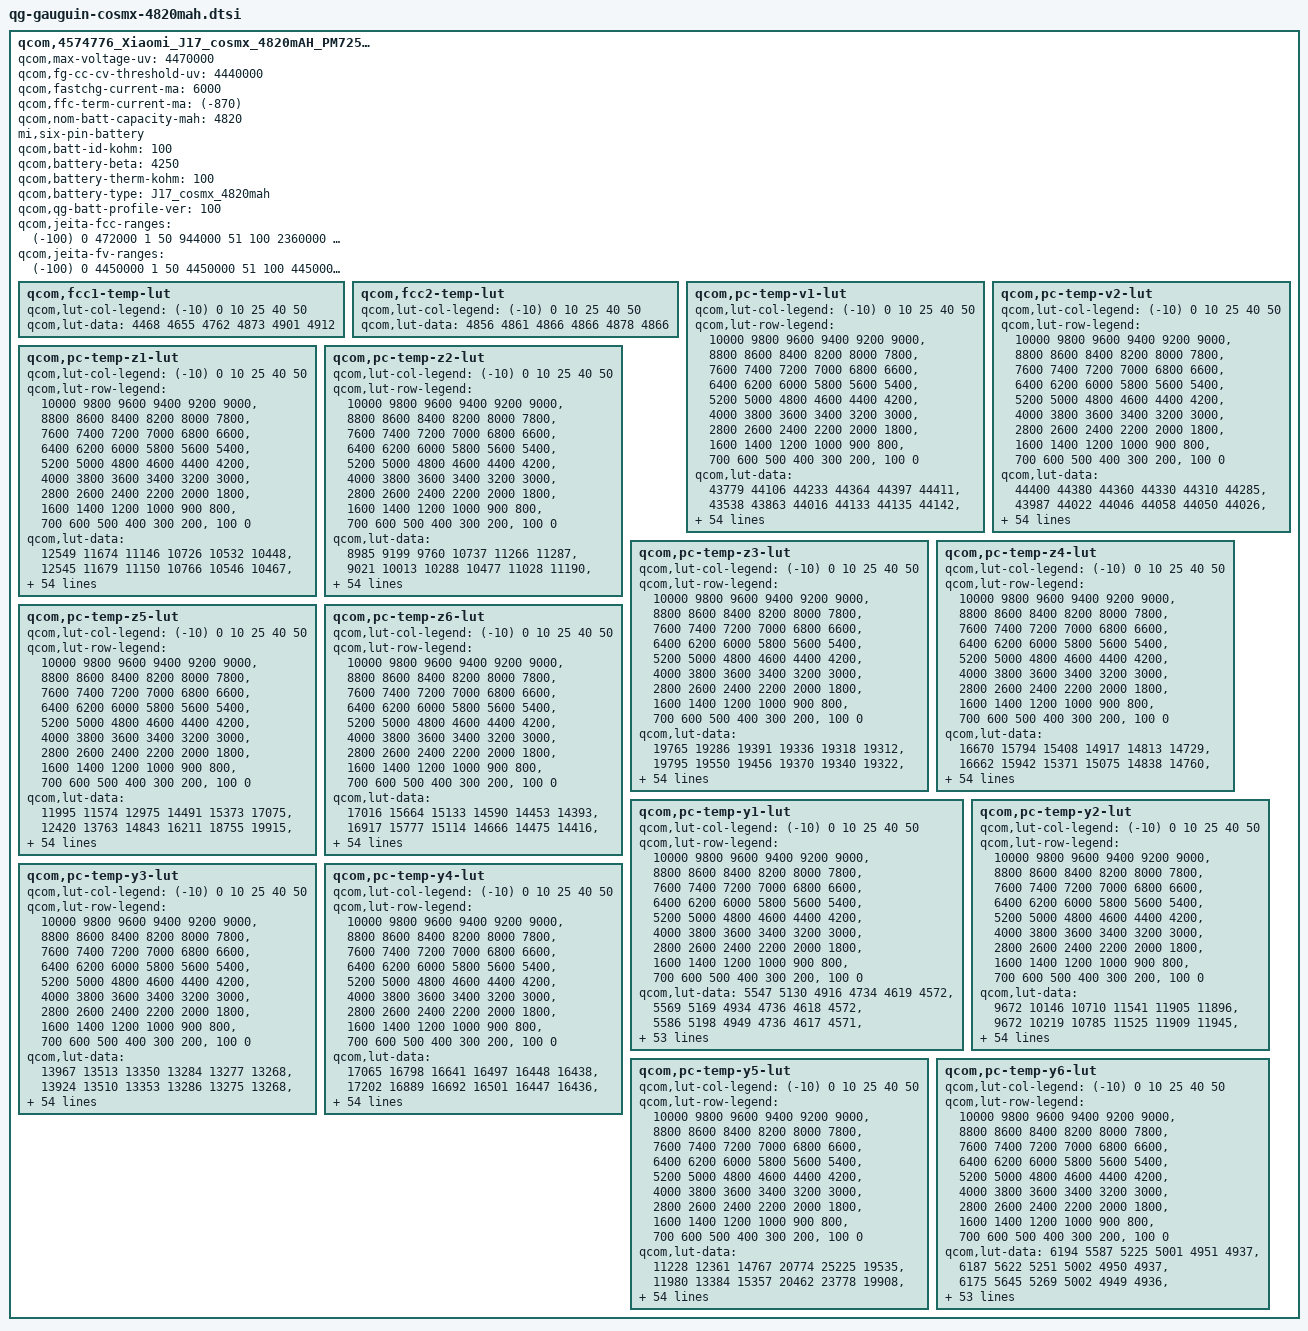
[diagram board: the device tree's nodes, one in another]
qcom,4574776_Xiaomi_J17_cosmx_4820mAH_PM7250B {
    /* 4574776_Xiaomi_J17_cosmx_4820mAH_PM7250B_averaged_MasterSlave_May19th2020 */
    qcom,max-voltage-uv = <4470000>;
    qcom,fg-cc-cv-threshold-uv = <4440000>;
    qcom,fastchg-current-ma = <6000>;
    qcom,ffc-term-current-ma = <(-870)>;
    qcom,nom-batt-capacity-mah = <4820>;
    mi,six-pin-battery;
    qcom,batt-id-kohm = <100>;
    qcom,battery-beta = <4250>;
    qcom,battery-therm-kohm = <100>;
    qcom,battery-type = "J17_cosmx_4820mah";
    qcom,qg-batt-profile-ver = <100>;
	qcom,jeita-fcc-ranges = <(-100)  0   472000
				1  50  944000
				51  100  2360000
				101 150  3776000
				151 480  6000000
				481 600  2360000>;
	qcom,jeita-fv-ranges = <(-100)  0   4450000
				1   50  4450000
				51  100  4450000
				101 150  4450000
				151 480  4480000
				481 600  4200000>;

	qcom,fcc1-temp-lut {
		qcom,lut-col-legend = <(-10) 0 10 25 40 50>;
		qcom,lut-data = <4468 4655 4762 4873 4901 4912>;
	};

	qcom,fcc2-temp-lut {
		qcom,lut-col-legend = <(-10) 0 10 25 40 50>;
		qcom,lut-data = <4856 4861 4866 4866 4878 4866>;
	};

	qcom,pc-temp-v1-lut {
		qcom,lut-col-legend = <(-10) 0 10 25 40 50>;
		qcom,lut-row-legend = <10000 9800 9600 9400 9200 9000>,
			<8800 8600 8400 8200 8000 7800>,
			<7600 7400 7200 7000 6800 6600>,
			<6400 6200 6000 5800 5600 5400>,
			<5200 5000 4800 4600 4400 4200>,
			<4000 3800 3600 3400 3200 3000>,
			<2800 2600 2400 2200 2000 1800>,
			<1600 1400 1200 1000 900 800>,
			<700 600 500 400 300 200>,
			<100 0>;
		qcom,lut-data = <43779 44106 44233 44364 44397 44411>,
			<43538 43863 44016 44133 44135 44142>,
			<43293 43634 43797 43920 43918 43921>,
			<43045 43409 43578 43709 43713 43713>,
			<42799 43176 43355 43490 43497 43498>,
			<42560 42937 43123 43266 43277 43282>,
			<42326 42697 42880 43033 43048 43057>,
			<42099 42457 42636 42791 42807 42822>,
			<41877 42218 42394 42544 42562 42580>,
			<41661 41984 42152 42298 42318 42337>,
			<41453 41756 41915 42051 42075 42091>,
			<41255 41534 41680 41811 41834 41850>,
			<41059 41315 41453 41575 41595 41614>,
			<40861 41102 41234 41344 41361 41381>,
			<40659 40894 41020 41121 41133 41153>,
			<40464 40694 40812 40905 40912 40930>,
			<40271 40499 40605 40696 40700 40714>,
			<40087 40304 40408 40493 40496 40507>,
			<39926 40110 40230 40300 40302 40309>,
			<39791 39931 40060 40126 40121 40125>,
			<39661 39782 39877 39950 39946 39949>,
			<39522 39641 39677 39727 39740 39747>,
			<39380 39484 39469 39461 39494 39509>,
			<39239 39309 39240 39239 39269 39284>,
			<39091 39130 39002 39075 39084 39096>,
			<38944 38941 38852 38934 38923 38929>,
			<38820 38753 38770 38808 38787 38789>,
			<38709 38632 38703 38695 38671 38670>,
			<38620 38561 38623 38594 38567 38561>,
			<38572 38505 38541 38503 38469 38459>,
			<38544 38454 38469 38422 38382 38366>,
			<38515 38410 38403 38349 38303 38281>,
			<38470 38368 38345 38284 38231 38203>,
			<38416 38329 38295 38226 38166 38133>,
			<38372 38292 38252 38177 38112 38075>,
			<38343 38257 38213 38130 38058 38018>,
			<38314 38226 38181 38086 38000 37949>,
			<38271 38188 38146 38043 37939 37869>,
			<38207 38125 38085 37983 37866 37784>,
			<38126 38037 37987 37893 37779 37696>,
			<38024 37933 37875 37785 37679 37597>,
			<37892 37801 37753 37664 37562 37480>,
			<37736 37657 37611 37522 37426 37343>,
			<37560 37500 37431 37353 37261 37177>,
			<37410 37362 37268 37191 37113 37034>,
			<37299 37253 37172 37094 37023 36953>,
			<37256 37214 37141 37066 36999 36933>,
			<37221 37179 37128 37049 36981 36919>,
			<37189 37146 37099 37031 36963 36903>,
			<37115 37089 37052 36980 36904 36834>,
			<36875 36845 36819 36703 36616 36526>,
			<36397 36367 36358 36246 36164 36076>,
			<35796 35757 35768 35647 35576 35487>,
			<34976 34918 34950 34828 34774 34681>,
			<33640 33576 33671 33540 33534 33435>,
			<30000 30000 30000 30000 30000 30000>;
	};

	qcom,pc-temp-v2-lut {
		qcom,lut-col-legend = <(-10) 0 10 25 40 50>;
		qcom,lut-row-legend = <10000 9800 9600 9400 9200 9000>,
			<8800 8600 8400 8200 8000 7800>,
			<7600 7400 7200 7000 6800 6600>,
			<6400 6200 6000 5800 5600 5400>,
			<5200 5000 4800 4600 4400 4200>,
			<4000 3800 3600 3400 3200 3000>,
			<2800 2600 2400 2200 2000 1800>,
			<1600 1400 1200 1000 900 800>,
			<700 600 500 400 300 200>,
			<100 0>;
		qcom,lut-data = <44400 44380 44360 44330 44310 44285>,
			<43987 44022 44046 44058 44050 44026>,
			<43613 43700 43759 43802 43803 43780>,
			<43287 43423 43505 43568 43573 43549>,
			<43003 43186 43284 43354 43359 43336>,
			<42732 42949 43058 43136 43140 43118>,
			<42461 42694 42811 42899 42905 42885>,
			<42198 42434 42559 42655 42664 42645>,
			<41933 42185 42310 42411 42423 42405>,
			<41661 41943 42063 42165 42178 42162>,
			<41451 41694 41819 41923 41936 41921>,
			<41328 41402 41578 41684 41696 41683>,
			<41217 41127 41341 41450 41461 41449>,
			<41035 40955 41113 41221 41231 41219>,
			<40766 40840 40892 40996 41007 40994>,
			<40474 40693 40675 40779 40789 40776>,
			<40157 40449 40459 40569 40577 40567>,
			<39843 40162 40248 40365 40371 40364>,
			<39595 39890 40054 40171 40178 40172>,
			<39389 39618 39872 39987 39995 39988>,
			<39172 39368 39668 39784 39795 39791>,
			<38902 39150 39414 39541 39565 39566>,
			<38657 38941 39157 39296 39334 39338>,
			<38518 38701 38944 39081 39120 39128>,
			<38423 38446 38753 38883 38917 38929>,
			<38341 38285 38587 38721 38755 38766>,
			<38266 38202 38445 38589 38628 38637>,
			<38199 38140 38314 38474 38517 38525>,
			<38134 38083 38181 38366 38412 38418>,
			<38072 38035 38053 38267 38314 38318>,
			<38009 37987 37971 38177 38224 38228>,
			<37943 37939 37921 38095 38140 38145>,
			<37877 37891 37881 38019 38063 38068>,
			<37812 37843 37845 37943 37993 37996>,
			<37747 37795 37812 37870 37926 37926>,
			<37679 37744 37773 37800 37842 37837>,
			<37610 37689 37727 37736 37733 37712>,
			<37534 37628 37670 37668 37623 37584>,
			<37448 37555 37596 37589 37527 37482>,
			<37352 37471 37503 37500 37435 37388>,
			<37258 37373 37394 37403 37339 37291>,
			<37164 37254 37260 37295 37240 37192>,
			<37078 37121 37121 37169 37121 37075>,
			<37003 36975 36979 37024 36982 36939>,
			<36930 36845 36861 36889 36855 36809>,
			<36844 36749 36766 36846 36830 36786>,
			<36795 36719 36720 36830 36816 36774>,
			<36745 36692 36671 36807 36801 36757>,
			<36677 36649 36608 36769 36764 36727>,
			<36551 36566 36486 36677 36642 36611>,
			<36302 36327 36255 36350 36267 36242>,
			<35873 35862 35825 35832 35742 35731>,
			<35235 35201 35172 35155 35058 35069>,
			<34322 34236 34254 34211 34098 34150>,
			<32809 32549 32696 32622 32565 32820>,
			<28196 27820 29481 28608 28869 29596>;
	};

	qcom,pc-temp-z1-lut {
		qcom,lut-col-legend = <(-10) 0 10 25 40 50>;
		qcom,lut-row-legend = <10000 9800 9600 9400 9200 9000>,
			<8800 8600 8400 8200 8000 7800>,
			<7600 7400 7200 7000 6800 6600>,
			<6400 6200 6000 5800 5600 5400>,
			<5200 5000 4800 4600 4400 4200>,
			<4000 3800 3600 3400 3200 3000>,
			<2800 2600 2400 2200 2000 1800>,
			<1600 1400 1200 1000 900 800>,
			<700 600 500 400 300 200>,
			<100 0>;
		qcom,lut-data = <12549 11674 11146 10726 10532 10448>,
			<12545 11679 11150 10766 10546 10467>,
			<12541 11677 11149 10762 10542 10465>,
			<12536 11672 11144 10755 10537 10463>,
			<12531 11665 11137 10748 10533 10461>,
			<12525 11658 11133 10739 10528 10457>,
			<12519 11651 11129 10732 10524 10455>,
			<12516 11636 11124 10724 10520 10453>,
			<12509 11613 11108 10718 10518 10451>,
			<12503 11594 11086 10714 10516 10450>,
			<12502 11580 11081 10711 10514 10450>,
			<12491 11565 11082 10710 10513 10449>,
			<12483 11546 11084 10710 10512 10448>,
			<12490 11525 11082 10710 10511 10447>,
			<12502 11517 11078 10711 10511 10447>,
			<12508 11530 11077 10711 10510 10447>,
			<12498 11545 11077 10712 10510 10447>,
			<12482 11544 11078 10712 10511 10448>,
			<12481 11534 11079 10712 10512 10449>,
			<12504 11528 11082 10713 10513 10450>,
			<12527 11530 11083 10714 10514 10451>,
			<12531 11533 11081 10716 10515 10452>,
			<12535 11535 11080 10719 10516 10452>,
			<12543 11535 11081 10721 10517 10452>,
			<12572 11536 11084 10725 10519 10454>,
			<12615 11537 11087 10730 10522 10456>,
			<12626 11539 11091 10732 10524 10459>,
			<12577 11543 11096 10735 10527 10461>,
			<12521 11552 11104 10737 10531 10463>,
			<12516 11562 11114 10740 10535 10465>,
			<12537 11567 11118 10743 10540 10467>,
			<12553 11572 11113 10743 10542 10468>,
			<12548 11576 11108 10743 10544 10470>,
			<12539 11580 11111 10744 10546 10473>,
			<12534 11583 11121 10748 10549 10475>,
			<12539 11584 11130 10752 10553 10479>,
			<12547 11586 11138 10756 10556 10481>,
			<12549 11589 11147 10760 10560 10484>,
			<12549 11599 11150 10765 10563 10486>,
			<12550 11616 11154 10771 10565 10487>,
			<12570 11622 11156 10776 10567 10489>,
			<12613 11622 11156 10777 10569 10490>,
			<12649 11627 11156 10778 10571 10492>,
			<12671 11649 11162 10780 10573 10493>,
			<12602 11658 11168 10786 10576 10494>,
			<12564 11654 11187 10785 10581 10496>,
			<12564 11673 11166 10790 10579 10496>,
			<12585 11660 11171 10792 10584 10498>,
			<12641 11655 11182 10791 10584 10497>,
			<12678 11670 11186 10793 10587 10500>,
			<12677 11677 11198 10806 10590 10504>,
			<12653 11716 11210 10803 10596 10506>,
			<12652 11707 11205 10815 10601 10512>,
			<12671 11708 11230 10829 10610 10519>,
			<12671 11708 11230 10829 10610 10519>,
			<12671 11708 11230 10829 10610 10519>;
	};

	qcom,pc-temp-z2-lut {
		qcom,lut-col-legend = <(-10) 0 10 25 40 50>;
		qcom,lut-row-legend = <10000 9800 9600 9400 9200 9000>,
			<8800 8600 8400 8200 8000 7800>,
			<7600 7400 7200 7000 6800 6600>,
			<6400 6200 6000 5800 5600 5400>,
			<5200 5000 4800 4600 4400 4200>,
			<4000 3800 3600 3400 3200 3000>,
			<2800 2600 2400 2200 2000 1800>,
			<1600 1400 1200 1000 900 800>,
			<700 600 500 400 300 200>,
			<100 0>;
		qcom,lut-data = <8985 9199 9760 10737 11266 11287>,
			<9021 10013 10288 10477 11028 11190>,
			<9201 10236 10523 10684 11044 11188>,
			<9765 10348 10511 10836 11041 11161>,
			<10180 10357 10487 10817 11028 11122>,
			<10184 10341 10460 10775 10978 11016>,
			<10165 10321 10423 10743 10937 10960>,
			<10147 10304 10391 10713 10910 10966>,
			<10134 10286 10365 10698 10890 10979>,
			<10122 10267 10345 10708 10891 11007>,
			<10082 10244 10346 10727 10917 11060>,
			<9863 10228 10370 10735 10932 11092>,
			<9665 10222 10395 10739 10948 11101>,
			<9728 10220 10405 10743 10960 11104>,
			<9965 10219 10413 10747 10954 11110>,
			<10101 10217 10425 10750 10946 11128>,
			<10102 10215 10448 10757 10951 11141>,
			<10103 10216 10466 10772 10980 11156>,
			<10077 10220 10471 10785 11011 11176>,
			<9864 10224 10474 10796 11034 11204>,
			<9661 10232 10482 10810 11052 11238>,
			<9714 10242 10520 10830 11057 11262>,
			<9942 10254 10552 10857 11056 11295>,
			<10083 10271 10540 10873 11051 11314>,
			<10088 10283 10508 10880 11028 11238>,
			<10090 10286 10493 10882 10991 11094>,
			<10090 10288 10492 10855 10965 11014>,
			<10088 10290 10492 10787 10943 10961>,
			<10085 10296 10494 10761 10923 10939>,
			<9967 10301 10498 10766 10897 10959>,
			<9469 10302 10502 10776 10877 10998>,
			<9106 10303 10507 10795 10887 11038>,
			<9149 10303 10514 10829 10937 11088>,
			<9254 10305 10524 10862 10988 11143>,
			<9296 10308 10538 10900 11050 11204>,
			<9236 10309 10544 10928 11107 11270>,
			<9152 10313 10544 10934 11141 11342>,
			<9111 10316 10545 10937 11177 11420>,
			<9087 10319 10552 10947 11214 11455>,
			<9072 10323 10576 10996 11278 11460>,
			<9068 10323 10588 11034 11331 11458>,
			<9065 10317 10574 11021 11335 11451>,
			<9057 10292 10564 10991 11314 11431>,
			<9045 10067 10565 10956 11269 11368>,
			<9039 10053 10609 10951 11258 11361>,
			<9038 10040 10626 10958 11254 11385>,
			<9034 10106 10587 10965 11231 11379>,
			<9032 10154 10436 10883 11237 11473>,
			<9033 10133 10436 10860 11245 11565>,
			<9031 10012 10430 10878 11336 11511>,
			<9023 9944 10379 10922 11125 11247>,
			<9018 9762 10422 10877 11066 11174>,
			<9013 9664 10254 10805 11014 11110>,
			<9007 9488 10123 10748 10932 11061>,
			<9007 9488 10123 10748 10932 11061>,
			<9007 9488 10123 10748 10932 11061>;
	};

	qcom,pc-temp-z3-lut {
		qcom,lut-col-legend = <(-10) 0 10 25 40 50>;
		qcom,lut-row-legend = <10000 9800 9600 9400 9200 9000>,
			<8800 8600 8400 8200 8000 7800>,
			<7600 7400 7200 7000 6800 6600>,
			<6400 6200 6000 5800 5600 5400>,
			<5200 5000 4800 4600 4400 4200>,
			<4000 3800 3600 3400 3200 3000>,
			<2800 2600 2400 2200 2000 1800>,
			<1600 1400 1200 1000 900 800>,
			<700 600 500 400 300 200>,
			<100 0>;
		qcom,lut-data = <19765 19286 19391 19336 19318 19312>,
			<19795 19550 19456 19370 19340 19322>,
			<19798 19613 19495 19395 19345 19329>,
			<19793 19645 19512 19407 19348 19333>,
			<19789 19658 19522 19410 19351 19334>,
			<19789 19666 19526 19412 19354 19334>,
			<19789 19669 19527 19411 19355 19334>,
			<19787 19669 19527 19405 19351 19330>,
			<19773 19668 19525 19399 19346 19325>,
			<19749 19667 19520 19396 19341 19324>,
			<19715 19659 19514 19394 19336 19323>,
			<19602 19650 19506 19392 19333 19322>,
			<19504 19641 19497 19389 19332 19318>,
			<19535 19633 19489 19386 19331 19314>,
			<19650 19625 19482 19382 19331 19313>,
			<19715 19617 19480 19379 19329 19312>,
			<19714 19610 19480 19376 19327 19311>,
			<19710 19605 19479 19374 19323 19310>,
			<19692 19600 19474 19372 19319 19309>,
			<19578 19595 19466 19372 19319 19308>,
			<19471 19587 19464 19372 19319 19306>,
			<19497 19579 19473 19374 19320 19307>,
			<19616 19580 19481 19379 19325 19313>,
			<19705 19591 19480 19384 19330 19320>,
			<19733 19601 19477 19386 19340 19326>,
			<19753 19604 19474 19389 19350 19331>,
			<19760 19605 19469 19395 19352 19332>,
			<19762 19605 19466 19405 19352 19331>,
			<19762 19603 19470 19408 19352 19330>,
			<19708 19599 19481 19404 19349 19327>,
			<19480 19595 19485 19398 19343 19323>,
			<19314 19590 19485 19393 19339 19320>,
			<19373 19586 19483 19389 19336 19317>,
			<19508 19583 19481 19386 19334 19314>,
			<19571 19581 19477 19383 19332 19311>,
			<19527 19577 19474 19381 19331 19309>,
			<19465 19573 19472 19380 19331 19309>,
			<19456 19569 19469 19380 19331 19311>,
			<19461 19565 19467 19378 19331 19312>,
			<19466 19562 19463 19376 19332 19315>,
			<19422 19558 19459 19373 19332 19317>,
			<19334 19552 19455 19371 19332 19316>,
			<19379 19533 19451 19370 19330 19314>,
			<19491 19412 19445 19365 19328 19315>,
			<19351 19292 19430 19359 19322 19313>,
			<19347 19262 19412 19349 19314 19305>,
			<19354 19262 19410 19349 19315 19305>,
			<19356 19261 19368 19345 19313 19299>,
			<19355 19262 19365 19339 19311 19294>,
			<19358 19262 19357 19337 19312 19298>,
			<19369 19263 19311 19342 19321 19310>,
			<19381 19265 19339 19344 19324 19307>,
			<19400 19267 19264 19344 19323 19308>,
			<19415 19272 19295 19341 19325 19308>,
			<19415 19272 19295 19341 19325 19308>,
			<19415 19272 19295 19341 19325 19308>;
	};

	qcom,pc-temp-z4-lut {
		qcom,lut-col-legend = <(-10) 0 10 25 40 50>;
		qcom,lut-row-legend = <10000 9800 9600 9400 9200 9000>,
			<8800 8600 8400 8200 8000 7800>,
			<7600 7400 7200 7000 6800 6600>,
			<6400 6200 6000 5800 5600 5400>,
			<5200 5000 4800 4600 4400 4200>,
			<4000 3800 3600 3400 3200 3000>,
			<2800 2600 2400 2200 2000 1800>,
			<1600 1400 1200 1000 900 800>,
			<700 600 500 400 300 200>,
			<100 0>;
		qcom,lut-data = <16670 15794 15408 14917 14813 14729>,
			<16662 15942 15371 15075 14838 14760>,
			<16585 15808 15309 14993 14812 14748>,
			<16274 15590 15198 14904 14771 14727>,
			<15953 15424 15062 14849 14743 14708>,
			<15776 15277 14969 14803 14720 14690>,
			<15636 15155 14899 14769 14704 14679>,
			<15532 15061 14845 14740 14694 14675>,
			<15447 14982 14803 14722 14687 14673>,
			<15382 14922 14769 14713 14683 14668>,
			<15360 14874 14748 14706 14680 14663>,
			<15404 14836 14733 14700 14676 14659>,
			<15446 14803 14723 14695 14671 14656>,
			<15399 14775 14718 14691 14665 14654>,
			<15276 14758 14715 14687 14659 14650>,
			<15208 14748 14712 14684 14655 14645>,
			<15211 14742 14710 14682 14652 14640>,
			<15217 14742 14708 14681 14651 14636>,
			<15228 14746 14707 14679 14650 14633>,
			<15281 14748 14706 14677 14648 14632>,
			<15329 14742 14707 14676 14646 14630>,
			<15304 14732 14716 14692 14653 14634>,
			<15214 14730 14733 14749 14692 14665>,
			<15159 14737 14773 14775 14718 14686>,
			<15210 14747 14836 14771 14712 14684>,
			<15302 14777 14856 14763 14701 14678>,
			<15341 14824 14836 14748 14691 14672>,
			<15346 14839 14808 14724 14680 14664>,
			<15350 14828 14786 14712 14672 14658>,
			<15385 14812 14765 14708 14670 14654>,
			<15502 14798 14753 14706 14668 14650>,
			<15585 14785 14747 14706 14666 14648>,
			<15524 14774 14744 14708 14665 14646>,
			<15388 14765 14744 14709 14664 14645>,
			<15326 14758 14744 14712 14665 14646>,
			<15349 14751 14744 14715 14667 14646>,
			<15382 14744 14740 14717 14672 14651>,
			<15381 14738 14736 14718 14681 14663>,
			<15361 14735 14736 14718 14684 14667>,
			<15342 14732 14738 14716 14681 14663>,
			<15363 14728 14739 14712 14677 14657>,
			<15412 14722 14727 14703 14670 14651>,
			<15380 14729 14712 14690 14662 14647>,
			<15311 14838 14704 14681 14657 14643>,
			<15358 14899 14683 14665 14651 14639>,
			<15338 14913 14668 14650 14641 14631>,
			<15328 14907 14663 14641 14631 14623>,
			<15316 14903 14696 14637 14623 14618>,
			<15303 14900 14693 14635 14617 14614>,
			<15286 14891 14700 14638 14618 14613>,
			<15292 14893 14757 14641 14619 14613>,
			<15347 14908 14733 14639 14617 14615>,
			<15384 14918 14814 14638 14617 14614>,
			<15456 14933 14788 14641 14617 14614>,
			<15456 14933 14788 14641 14617 14614>,
			<15456 14933 14788 14641 14617 14614>;
	};

	qcom,pc-temp-z5-lut {
		qcom,lut-col-legend = <(-10) 0 10 25 40 50>;
		qcom,lut-row-legend = <10000 9800 9600 9400 9200 9000>,
			<8800 8600 8400 8200 8000 7800>,
			<7600 7400 7200 7000 6800 6600>,
			<6400 6200 6000 5800 5600 5400>,
			<5200 5000 4800 4600 4400 4200>,
			<4000 3800 3600 3400 3200 3000>,
			<2800 2600 2400 2200 2000 1800>,
			<1600 1400 1200 1000 900 800>,
			<700 600 500 400 300 200>,
			<100 0>;
		qcom,lut-data = <11995 11574 12975 14491 15373 17075>,
			<12420 13763 14843 16211 18755 19915>,
			<12988 14638 16317 18024 19568 21087>,
			<13757 15242 17335 19336 20114 22168>,
			<14392 15890 18204 20254 20864 23114>,
			<14744 16495 19245 20988 21748 24017>,
			<15010 17196 20440 21721 22275 24357>,
			<15108 18181 21741 22441 22568 23694>,
			<15050 19353 23251 23128 22732 22888>,
			<14963 20462 24918 23839 22393 23040>,
			<14824 21478 26578 24513 21567 23779>,
			<13897 22575 28455 25054 21333 24054>,
			<13047 24010 29578 25651 21884 23227>,
			<13545 25729 29673 26011 22669 22368>,
			<15163 27183 29675 26120 23515 22638>,
			<16068 28459 30260 26234 24393 23643>,
			<16026 29440 33724 26552 24511 24625>,
			<15927 29870 36472 27336 23737 25655>,
			<15661 30117 34847 28242 23121 26672>,
			<14312 30197 31399 30021 24309 27682>,
			<13062 29906 31385 31815 26306 28591>,
			<13483 29481 42097 32186 26369 28478>,
			<15390 31146 51660 32194 24469 26088>,
			<17075 42300 49132 31802 22938 23765>,
			<18023 51445 41391 27632 22392 22620>,
			<18748 52197 35336 23158 22118 21833>,
			<18925 52512 30445 24240 22768 22004>,
			<18708 52335 27400 28979 25424 23652>,
			<18281 48550 28382 32690 27717 25412>,
			<17082 43765 32038 34946 28867 26663>,
			<13737 41213 35635 36788 29896 27894>,
			<11408 39251 39203 38412 31299 29412>,
			<11774 38525 42217 39829 33088 31229>,
			<12665 38742 43776 40798 35054 32543>,
			<13057 39057 44870 41857 37765 33453>,
			<12717 39105 45290 42555 39780 34009>,
			<12254 38870 45028 42172 38892 33250>,
			<12156 38841 44488 40958 36113 30930>,
			<12140 39869 43870 39433 34763 30178>,
			<12103 41451 42833 36877 34349 32853>,
			<11786 41751 41693 35154 34140 35441>,
			<11199 39860 40120 35306 34244 35146>,
			<11425 36206 38614 35563 34348 34333>,
			<12123 24719 37187 32232 32250 34771>,
			<10987 14145 37361 32619 28126 32404>,
			<10882 11476 32469 31860 26449 27679>,
			<10872 11386 32469 34925 29932 30889>,
			<10837 11355 17911 33751 35311 32409>,
			<10763 11326 17573 29521 39877 31684>,
			<10759 11318 16766 26671 35254 33039>,
			<10805 11435 14155 25324 36533 42977>,
			<10804 11383 14430 25673 40662 33644>,
			<10721 11310 11661 24833 37958 33944>,
			<10607 11206 12290 22910 38372 33033>,
			<10607 11206 12290 22910 38372 33033>,
			<10607 11206 12290 22910 38372 33033>;
	};

	qcom,pc-temp-z6-lut {
		qcom,lut-col-legend = <(-10) 0 10 25 40 50>;
		qcom,lut-row-legend = <10000 9800 9600 9400 9200 9000>,
			<8800 8600 8400 8200 8000 7800>,
			<7600 7400 7200 7000 6800 6600>,
			<6400 6200 6000 5800 5600 5400>,
			<5200 5000 4800 4600 4400 4200>,
			<4000 3800 3600 3400 3200 3000>,
			<2800 2600 2400 2200 2000 1800>,
			<1600 1400 1200 1000 900 800>,
			<700 600 500 400 300 200>,
			<100 0>;
		qcom,lut-data = <17016 15664 15133 14590 14453 14393>,
			<16917 15777 15114 14666 14475 14416>,
			<16777 15695 15080 14638 14465 14413>,
			<16578 15559 15016 14604 14449 14406>,
			<16400 15449 14932 14578 14438 14399>,
			<16293 15346 14871 14553 14428 14392>,
			<16210 15257 14821 14533 14420 14385>,
			<16144 15186 14780 14513 14413 14381>,
			<16091 15125 14745 14500 14407 14377>,
			<16047 15075 14716 14493 14402 14374>,
			<16005 15032 14697 14488 14398 14372>,
			<15959 14996 14682 14483 14394 14369>,
			<15926 14965 14672 14479 14391 14365>,
			<15915 14938 14665 14475 14388 14362>,
			<15910 14921 14659 14471 14385 14359>,
			<15909 14910 14656 14468 14382 14357>,
			<15913 14903 14654 14466 14379 14355>,
			<15916 14901 14652 14464 14377 14352>,
			<15915 14900 14648 14463 14375 14350>,
			<15892 14898 14644 14462 14374 14349>,
			<15871 14893 14643 14462 14374 14348>,
			<15875 14888 14652 14470 14377 14350>,
			<15902 14888 14666 14499 14397 14367>,
			<15936 14898 14687 14512 14411 14380>,
			<15985 14912 14713 14512 14414 14382>,
			<16043 14930 14720 14512 14415 14384>,
			<16075 14952 14711 14511 14415 14383>,
			<16092 14958 14700 14507 14410 14380>,
			<16102 14954 14696 14504 14406 14376>,
			<16090 14948 14693 14501 14403 14372>,
			<16036 14943 14692 14498 14400 14369>,
			<15996 14938 14691 14497 14398 14367>,
			<15999 14934 14691 14496 14396 14364>,
			<16007 14932 14691 14496 14395 14363>,
			<16011 14930 14692 14497 14395 14361>,
			<16011 14929 14693 14499 14396 14360>,
			<16010 14929 14694 14500 14398 14363>,
			<16013 14930 14694 14502 14403 14369>,
			<16020 14933 14696 14503 14404 14372>,
			<16028 14939 14700 14503 14404 14371>,
			<16035 14942 14702 14502 14403 14370>,
			<16042 14944 14700 14499 14400 14368>,
			<16063 14946 14697 14494 14396 14365>,
			<16092 14946 14697 14490 14394 14365>,
			<16087 14932 14692 14483 14389 14362>,
			<16083 14929 14682 14475 14381 14354>,
			<16086 14928 14680 14472 14377 14351>,
			<16085 14926 14673 14469 14373 14346>,
			<16085 14928 14673 14466 14370 14341>,
			<16095 14931 14678 14468 14372 14343>,
			<16125 14941 14684 14474 14378 14351>,
			<16177 14958 14694 14478 14380 14351>,
			<16228 14972 14700 14481 14381 14352>,
			<16310 14998 14716 14485 14384 14354>,
			<16310 14998 14716 14485 14384 14354>,
			<16310 14998 14716 14485 14384 14354>;
	};

	qcom,pc-temp-y1-lut {
		qcom,lut-col-legend = <(-10) 0 10 25 40 50>;
		qcom,lut-row-legend = <10000 9800 9600 9400 9200 9000>,
			<8800 8600 8400 8200 8000 7800>,
			<7600 7400 7200 7000 6800 6600>,
			<6400 6200 6000 5800 5600 5400>,
			<5200 5000 4800 4600 4400 4200>,
			<4000 3800 3600 3400 3200 3000>,
			<2800 2600 2400 2200 2000 1800>,
			<1600 1400 1200 1000 900 800>,
			<700 600 500 400 300 200>,
			<100 0>;
		qcom,lut-data = <5547 5130 4916 4734 4619 4572>,
			<5569 5169 4934 4736 4618 4572>,
			<5586 5198 4949 4736 4617 4571>,
			<5598 5219 4961 4736 4616 4570>,
			<5606 5232 4969 4735 4615 4569>,
			<5608 5236 4972 4735 4614 4568>,
			<5602 5226 4970 4734 4613 4567>,
			<5594 5212 4966 4733 4612 4565>,
			<5596 5213 4962 4731 4610 4564>,
			<5608 5225 4954 4729 4608 4564>,
			<5617 5233 4951 4728 4606 4563>,
			<5618 5232 4951 4728 4605 4564>,
			<5619 5230 4951 4729 4603 4564>,
			<5620 5229 4951 4729 4602 4564>,
			<5620 5228 4951 4727 4602 4563>,
			<5620 5227 4951 4726 4602 4562>,
			<5620 5228 4954 4725 4602 4562>,
			<5619 5229 4958 4725 4601 4562>,
			<5622 5229 4963 4725 4601 4561>,
			<5630 5230 4969 4727 4600 4561>,
			<5636 5230 4972 4729 4600 4560>,
			<5636 5231 4973 4730 4602 4561>,
			<5634 5232 4973 4732 4603 4562>,
			<5629 5233 4970 4732 4604 4562>,
			<5617 5234 4965 4732 4605 4562>,
			<5611 5235 4963 4732 4605 4562>,
			<5621 5241 4963 4735 4606 4563>,
			<5631 5248 4964 4738 4606 4565>,
			<5629 5246 4965 4740 4607 4566>,
			<5621 5239 4969 4742 4609 4567>,
			<5614 5236 4971 4743 4611 4568>,
			<5610 5232 4974 4743 4612 4569>,
			<5607 5227 4977 4743 4613 4569>,
			<5617 5227 4973 4745 4615 4571>,
			<5643 5227 4966 4748 4617 4572>,
			<5650 5228 4965 4749 4618 4574>,
			<5625 5232 4969 4749 4619 4575>,
			<5601 5235 4972 4749 4620 4576>,
			<5600 5235 4972 4751 4622 4578>,
			<5601 5234 4973 4755 4624 4580>,
			<5601 5236 4972 4759 4625 4581>,
			<5602 5245 4968 4766 4626 4581>,
			<5608 5248 4968 4768 4627 4581>,
			<5646 5247 4978 4764 4630 4583>,
			<5651 5245 4980 4763 4633 4584>,
			<5640 5256 4986 4767 4632 4585>,
			<5662 5259 4984 4769 4634 4585>,
			<5644 5260 4988 4780 4635 4586>,
			<5647 5250 4982 4770 4634 4587>,
			<5656 5254 4988 4771 4636 4586>,
			<5668 5268 4992 4782 4636 4587>,
			<5740 5280 5004 4783 4639 4589>,
			<5826 5313 5022 4790 4645 4593>,
			<5872 5359 5030 4800 4650 4598>,
			<5872 5359 5030 4800 4650 4598>,
			<5872 5359 5030 4800 4650 4598>;
	};

	qcom,pc-temp-y2-lut {
		qcom,lut-col-legend = <(-10) 0 10 25 40 50>;
		qcom,lut-row-legend = <10000 9800 9600 9400 9200 9000>,
			<8800 8600 8400 8200 8000 7800>,
			<7600 7400 7200 7000 6800 6600>,
			<6400 6200 6000 5800 5600 5400>,
			<5200 5000 4800 4600 4400 4200>,
			<4000 3800 3600 3400 3200 3000>,
			<2800 2600 2400 2200 2000 1800>,
			<1600 1400 1200 1000 900 800>,
			<700 600 500 400 300 200>,
			<100 0>;
		qcom,lut-data = <9672 10146 10710 11541 11905 11896>,
			<9672 10219 10785 11525 11909 11945>,
			<9672 10320 10881 11493 11877 11966>,
			<9672 10426 10975 11455 11825 11968>,
			<9672 10513 11046 11424 11772 11955>,
			<9672 10559 11073 11411 11733 11935>,
			<9673 10572 11062 11397 11680 11875>,
			<9674 10581 11043 11373 11614 11789>,
			<9674 10607 11033 11350 11572 11724>,
			<9674 10664 11025 11315 11533 11660>,
			<9674 10693 11014 11288 11512 11629>,
			<9674 10653 10984 11271 11517 11627>,
			<9674 10601 10953 11260 11526 11632>,
			<9674 10650 10974 11264 11513 11651>,
			<9673 10871 11074 11287 11488 11693>,
			<9672 11015 11166 11315 11479 11712>,
			<9671 11061 11228 11345 11501 11705>,
			<9670 11086 11287 11386 11542 11689>,
			<9670 10859 11366 11472 11597 11664>,
			<9669 10094 11459 11616 11680 11629>,
			<9669 9727 11490 11677 11752 11621>,
			<9668 9711 11414 11680 11836 11781>,
			<9667 9701 11319 11680 11900 11971>,
			<9667 9694 11285 11659 11916 12015>,
			<9667 9688 11266 11607 11926 12028>,
			<9666 9683 11233 11586 11942 12048>,
			<9666 9680 11147 11626 11975 12087>,
			<9666 9678 11032 11668 12009 12139>,
			<9665 9675 10912 11674 12039 12213>,
			<9665 9673 10776 11686 12068 12304>,
			<9665 9671 10637 11704 12084 12336>,
			<9665 9669 10495 11746 12120 12304>,
			<9665 9668 10352 11778 12163 12276>,
			<9665 9667 10207 11746 12206 12316>,
			<9664 9666 10062 11665 12251 12396>,
			<9664 9665 9942 11628 12250 12426>,
			<9664 9664 9834 11626 12166 12423>,
			<9664 9664 9759 11620 12080 12411>,
			<9664 9663 9724 11566 12033 12384>,
			<9663 9663 9701 11479 12000 12338>,
			<9663 9662 9689 11428 12002 12307>,
			<9663 9662 9681 11401 12035 12285>,
			<9663 9662 9676 11377 12032 12233>,
			<9662 9661 9671 11345 12005 12129>,
			<9661 9661 9668 11211 11940 12215>,
			<9661 9660 9667 11267 11904 12067>,
			<9660 9660 9666 11218 11882 11948>,
			<9660 9660 9665 11254 11757 11813>,
			<9659 9659 9663 11184 11731 11801>,
			<9657 9658 9662 11203 11780 11827>,
			<9654 9658 9661 11112 11682 11772>,
			<9652 9656 9660 10990 11577 11714>,
			<9651 9654 9658 10894 11536 11643>,
			<9649 9651 9657 10808 11469 11600>,
			<9649 9651 9657 10808 11469 11600>,
			<9649 9651 9657 10808 11469 11600>;
	};

	qcom,pc-temp-y3-lut {
		qcom,lut-col-legend = <(-10) 0 10 25 40 50>;
		qcom,lut-row-legend = <10000 9800 9600 9400 9200 9000>,
			<8800 8600 8400 8200 8000 7800>,
			<7600 7400 7200 7000 6800 6600>,
			<6400 6200 6000 5800 5600 5400>,
			<5200 5000 4800 4600 4400 4200>,
			<4000 3800 3600 3400 3200 3000>,
			<2800 2600 2400 2200 2000 1800>,
			<1600 1400 1200 1000 900 800>,
			<700 600 500 400 300 200>,
			<100 0>;
		qcom,lut-data = <13967 13513 13350 13284 13277 13268>,
			<13924 13510 13353 13286 13275 13268>,
			<13884 13507 13357 13287 13274 13269>,
			<13846 13505 13360 13289 13273 13269>,
			<13813 13503 13363 13290 13273 13270>,
			<13786 13501 13364 13290 13273 13270>,
			<13767 13500 13364 13291 13274 13271>,
			<13749 13499 13363 13291 13274 13271>,
			<13721 13499 13364 13291 13274 13272>,
			<13679 13500 13366 13291 13275 13272>,
			<13657 13499 13367 13292 13275 13273>,
			<13653 13460 13369 13293 13275 13273>,
			<13651 13408 13370 13294 13275 13273>,
			<13653 13408 13366 13295 13276 13273>,
			<13658 13431 13353 13296 13279 13274>,
			<13661 13443 13346 13297 13280 13274>,
			<13641 13429 13346 13297 13280 13276>,
			<13616 13412 13345 13298 13279 13277>,
			<13616 13410 13344 13297 13280 13277>,
			<13625 13411 13342 13296 13280 13275>,
			<13629 13411 13339 13295 13280 13275>,
			<13621 13412 13333 13293 13280 13275>,
			<13613 13412 13325 13291 13279 13275>,
			<13617 13406 13320 13288 13277 13274>,
			<13639 13387 13316 13285 13273 13270>,
			<13663 13379 13313 13284 13272 13269>,
			<13688 13395 13309 13284 13272 13269>,
			<13715 13419 13305 13283 13273 13269>,
			<13743 13443 13301 13283 13273 13269>,
			<13771 13470 13296 13283 13273 13269>,
			<13800 13500 13295 13283 13273 13269>,
			<13831 13533 13297 13283 13273 13269>,
			<13863 13570 13299 13282 13272 13269>,
			<13897 13612 13304 13282 13272 13269>,
			<13933 13661 13313 13282 13273 13270>,
			<13969 13711 13323 13281 13273 13269>,
			<14005 13765 13335 13281 13272 13268>,
			<14040 13819 13350 13281 13271 13267>,
			<14072 13871 13367 13281 13270 13268>,
			<14103 13922 13387 13281 13270 13268>,
			<14134 13965 13410 13281 13270 13268>,
			<14163 13999 13441 13283 13272 13269>,
			<14197 14031 13480 13286 13272 13270>,
			<14239 14063 13531 13289 13271 13270>,
			<14311 14109 13588 13289 13271 13268>,
			<14349 14129 13601 13289 13272 13270>,
			<14424 14181 13649 13292 13273 13270>,
			<14519 14239 13717 13294 13276 13272>,
			<14654 14308 13787 13298 13278 13274>,
			<14868 14403 13851 13302 13278 13273>,
			<15409 14531 13934 13300 13277 13271>,
			<16953 14788 14053 13302 13277 13272>,
			<20608 15579 14287 13310 13279 13274>,
			<30005 17903 14627 13324 13281 13275>,
			<30005 17903 14627 13324 13281 13275>,
			<30005 17903 14627 13324 13281 13275>;
	};

	qcom,pc-temp-y4-lut {
		qcom,lut-col-legend = <(-10) 0 10 25 40 50>;
		qcom,lut-row-legend = <10000 9800 9600 9400 9200 9000>,
			<8800 8600 8400 8200 8000 7800>,
			<7600 7400 7200 7000 6800 6600>,
			<6400 6200 6000 5800 5600 5400>,
			<5200 5000 4800 4600 4400 4200>,
			<4000 3800 3600 3400 3200 3000>,
			<2800 2600 2400 2200 2000 1800>,
			<1600 1400 1200 1000 900 800>,
			<700 600 500 400 300 200>,
			<100 0>;
		qcom,lut-data = <17065 16798 16641 16497 16448 16438>,
			<17202 16889 16692 16501 16447 16436>,
			<17302 16993 16757 16504 16447 16434>,
			<17368 17091 16820 16505 16446 16433>,
			<17404 17163 16867 16506 16445 16431>,
			<17414 17189 16885 16506 16445 16430>,
			<17377 17176 16878 16504 16444 16430>,
			<17325 17150 16865 16501 16443 16429>,
			<17317 17128 16853 16499 16443 16430>,
			<17320 17104 16840 16499 16445 16430>,
			<17325 17094 16828 16498 16447 16430>,
			<17377 17135 16818 16500 16449 16432>,
			<17442 17196 16811 16503 16451 16434>,
			<17428 17225 16823 16506 16452 16436>,
			<17325 17246 16866 16511 16453 16439>,
			<17214 17252 16887 16518 16454 16442>,
			<17109 17199 16884 16530 16460 16444>,
			<17008 17114 16881 16546 16470 16448>,
			<16937 17051 16880 16572 16485 16456>,
			<16881 16995 16879 16608 16504 16473>,
			<16822 16936 16875 16621 16511 16480>,
			<16736 16871 16814 16597 16507 16479>,
			<16667 16803 16732 16559 16500 16475>,
			<16657 16719 16684 16527 16483 16464>,
			<16655 16622 16646 16495 16454 16443>,
			<16654 16586 16616 16482 16445 16435>,
			<16657 16584 16595 16480 16445 16435>,
			<16661 16585 16575 16479 16445 16435>,
			<16665 16589 16544 16480 16446 16436>,
			<16668 16597 16509 16483 16449 16439>,
			<16673 16606 16499 16486 16453 16443>,
			<16680 16617 16512 16490 16459 16448>,
			<16688 16630 16532 16492 16465 16453>,
			<16701 16642 16552 16490 16472 16459>,
			<16719 16654 16574 16484 16479 16465>,
			<16727 16665 16596 16478 16478 16465>,
			<16728 16676 16619 16472 16459 16451>,
			<16727 16683 16639 16468 16442 16437>,
			<16720 16686 16651 16467 16437 16432>,
			<16706 16688 16661 16466 16434 16428>,
			<16699 16688 16662 16468 16433 16428>,
			<16695 16681 16661 16480 16434 16428>,
			<16695 16671 16659 16493 16436 16429>,
			<16705 16659 16658 16506 16440 16431>,
			<16721 16648 16667 16505 16433 16424>,
			<16715 16636 16665 16498 16439 16427>,
			<16735 16650 16690 16505 16443 16432>,
			<16758 16669 16732 16520 16447 16436>,
			<16781 16698 16797 16546 16464 16457>,
			<16792 16738 16864 16580 16481 16479>,
			<16814 16733 16911 16548 16449 16435>,
			<17018 16711 16902 16554 16456 16439>,
			<17816 16827 16907 16586 16476 16453>,
			<21863 17688 16935 16643 16520 16487>,
			<21863 17688 16935 16643 16520 16487>,
			<21863 17688 16935 16643 16520 16487>;
	};

	qcom,pc-temp-y5-lut {
		qcom,lut-col-legend = <(-10) 0 10 25 40 50>;
		qcom,lut-row-legend = <10000 9800 9600 9400 9200 9000>,
			<8800 8600 8400 8200 8000 7800>,
			<7600 7400 7200 7000 6800 6600>,
			<6400 6200 6000 5800 5600 5400>,
			<5200 5000 4800 4600 4400 4200>,
			<4000 3800 3600 3400 3200 3000>,
			<2800 2600 2400 2200 2000 1800>,
			<1600 1400 1200 1000 900 800>,
			<700 600 500 400 300 200>,
			<100 0>;
		qcom,lut-data = <11228 12361 14767 20774 25225 19535>,
			<11980 13384 15357 20462 23778 19908>,
			<12725 14373 15970 20266 22098 20279>,
			<13419 15292 16552 20156 20476 20626>,
			<14017 16103 17049 20100 19205 20925>,
			<14474 16768 17406 20064 18577 21154>,
			<14862 17287 17637 19724 18523 21350>,
			<15137 17735 17825 19270 18571 21488>,
			<15059 18230 18046 19055 18324 21473>,
			<14564 18802 18301 18449 17711 21297>,
			<14297 19028 18409 18108 17184 21045>,
			<15442 16994 18371 17939 16759 20532>,
			<17545 14346 18278 17702 16459 19866>,
			<19692 15128 17740 17553 16793 19272>,
			<22293 19338 16168 17315 18013 18589>,
			<23370 21452 15432 17017 18535 18327>,
			<21467 21232 15920 16479 17500 18823>,
			<19117 20853 16843 16008 16278 19407>,
			<19548 20457 18100 16011 16014 18843>,
			<21964 19992 19941 16228 15898 16853>,
			<23007 19868 21290 16685 16048 16081>,
			<18957 21566 22093 19517 19126 18967>,
			<14156 23465 22711 22490 22189 22100>,
			<13426 21655 23198 22842 21803 22033>,
			<13250 15772 23588 22676 20443 21154>,
			<13174 13278 24036 22592 20079 20834>,
			<13201 13450 24716 22707 21312 21360>,
			<13286 13673 25202 22821 22604 21881>,
			<13454 13799 23160 22812 22872 21523>,
			<13785 14094 17874 22805 22729 20503>,
			<13973 14307 15604 22944 22307 19981>,
			<14042 14387 15149 23527 21062 19788>,
			<14089 14460 14947 24246 20214 19692>,
			<14113 14717 15275 24913 20720 19960>,
			<14129 15221 16094 25571 21870 20658>,
			<14242 15694 16585 25687 22712 21156>,
			<14657 16286 16843 25077 23412 21431>,
			<15004 16762 17019 24264 23750 21773>,
			<14966 16968 17142 22939 23106 22788>,
			<14787 17138 17231 20939 22057 24356>,
			<14510 17067 17207 19884 22235 25328>,
			<13868 16421 16864 19303 24006 26413>,
			<13491 15642 16531 19153 23327 26845>,
			<13363 14825 16224 19249 20586 27276>,
			<13529 14516 15649 19422 22937 25907>,
			<13652 14078 15337 20447 20854 23936>,
			<13702 14263 15491 20226 19896 21063>,
			<13963 14403 15906 19347 22335 23298>,
			<14348 14319 16407 19001 22459 23843>,
			<14381 14538 16705 19591 23232 20797>,
			<13823 14339 16858 20642 26514 25990>,
			<12013 14243 15981 19948 26482 25725>,
			<10291 13003 14119 19703 27717 28326>,
			<9288 10626 13129 19541 26057 27364>,
			<9288 10626 13129 19541 26057 27364>,
			<9288 10626 13129 19541 26057 27364>;
	};

	qcom,pc-temp-y6-lut {
		qcom,lut-col-legend = <(-10) 0 10 25 40 50>;
		qcom,lut-row-legend = <10000 9800 9600 9400 9200 9000>,
			<8800 8600 8400 8200 8000 7800>,
			<7600 7400 7200 7000 6800 6600>,
			<6400 6200 6000 5800 5600 5400>,
			<5200 5000 4800 4600 4400 4200>,
			<4000 3800 3600 3400 3200 3000>,
			<2800 2600 2400 2200 2000 1800>,
			<1600 1400 1200 1000 900 800>,
			<700 600 500 400 300 200>,
			<100 0>;
		qcom,lut-data = <6194 5587 5225 5001 4951 4937>,
			<6187 5622 5251 5002 4950 4937>,
			<6175 5645 5269 5002 4949 4936>,
			<6159 5660 5282 5003 4949 4936>,
			<6140 5668 5288 5003 4948 4936>,
			<6118 5670 5290 5003 4948 4936>,
			<6092 5662 5285 5002 4948 4936>,
			<6064 5649 5276 5001 4948 4936>,
			<6036 5641 5269 5000 4948 4937>,
			<6007 5636 5263 4999 4948 4937>,
			<5995 5629 5257 4999 4949 4938>,
			<6007 5612 5252 5000 4949 4938>,
			<6022 5596 5248 5001 4950 4939>,
			<6019 5601 5248 5002 4951 4940>,
			<5996 5629 5249 5004 4953 4941>,
			<5967 5642 5250 5007 4955 4942>,
			<5924 5625 5249 5010 4957 4943>,
			<5881 5596 5247 5015 4958 4945>,
			<5865 5571 5247 5022 4962 4948>,
			<5856 5547 5246 5032 4969 4952>,
			<5845 5528 5244 5035 4971 4953>,
			<5820 5515 5223 5027 4969 4953>,
			<5799 5503 5196 5014 4966 4951>,
			<5801 5485 5182 5004 4960 4947>,
			<5818 5461 5171 4992 4949 4939>,
			<5838 5453 5164 4989 4945 4936>,
			<5858 5471 5160 4988 4946 4936>,
			<5880 5500 5156 4988 4946 4936>,
			<5902 5528 5150 4989 4947 4936>,
			<5925 5558 5144 4990 4948 4937>,
			<5949 5591 5143 4992 4949 4938>,
			<5974 5625 5156 4994 4951 4940>,
			<6000 5662 5176 4996 4952 4942>,
			<6028 5702 5197 4995 4955 4944>,
			<6058 5746 5222 4994 4957 4945>,
			<6088 5790 5249 4993 4957 4945>,
			<6118 5835 5279 4993 4951 4941>,
			<6146 5880 5313 4992 4946 4936>,
			<6169 5924 5348 4993 4944 4935>,
			<6191 5966 5387 4994 4943 4935>,
			<6214 6000 5427 4996 4944 4935>,
			<6238 6027 5469 5004 4945 4935>,
			<6268 6052 5517 5012 4946 4936>,
			<6309 6077 5573 5021 4947 4938>,
			<6372 6111 5634 5025 4945 4934>,
			<6410 6129 5649 5023 4948 4937>,
			<6478 6177 5699 5028 4950 4938>,
			<6564 6229 5768 5037 4954 4941>,
			<6684 6293 5846 5050 4960 4948>,
			<6865 6380 5922 5066 4965 4954>,
			<7320 6484 6007 5057 4955 4940>,
			<8591 6687 6105 5067 4957 4942>,
			<11523 7355 6297 5094 4966 4948>,
			<19124 9359 6578 5136 4981 4960>,
			<19124 9359 6578 5136 4981 4960>,
			<19124 9359 6578 5136 4981 4960>;
	};

};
